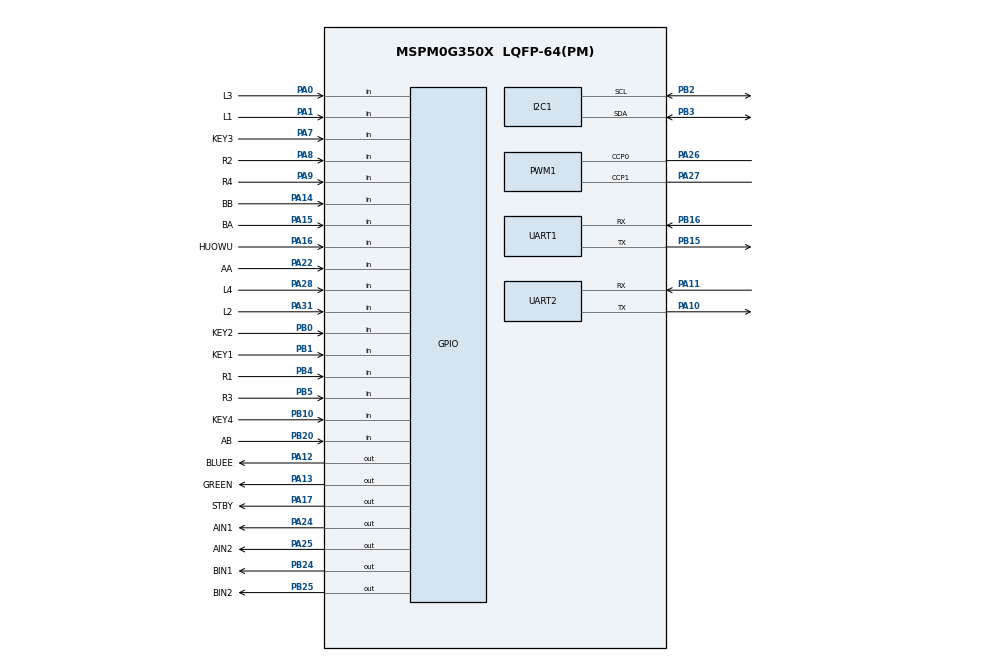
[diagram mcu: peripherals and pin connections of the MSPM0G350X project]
/**
 * @cliArgs --device "MSPM0G350X" --part "Default" --package "LQFP-64(PM)" --product "mspm0_sdk@2.11.00.07"
 * @versions {"tool":"1.26.2+4477"}
 */

/**
 * Import the modules used in this configuration.
 */
const GPIO   = scripting.addModule("/ti/driverlib/GPIO", {}, false);
const GPIO1  = GPIO.addInstance();
const GPIO2  = GPIO.addInstance();
const GPIO3  = GPIO.addInstance();
const GPIO4  = GPIO.addInstance();
const I2C    = scripting.addModule("/ti/driverlib/I2C", {}, false);
const I2C1   = I2C.addInstance();
const PWM    = scripting.addModule("/ti/driverlib/PWM", {}, false);
const PWM1   = PWM.addInstance();
const SYSCTL = scripting.addModule("/ti/driverlib/SYSCTL");
const TIMER  = scripting.addModule("/ti/driverlib/TIMER", {}, false);
const TIMER1 = TIMER.addInstance();
const UART   = scripting.addModule("/ti/driverlib/UART", {}, false);
const UART1  = UART.addInstance();
const UART2  = UART.addInstance();

/**
 * Write custom configuration values to the imported modules.
 */
const divider9       = system.clockTree["UDIV"];
divider9.divideValue = 2;

const multiplier2         = system.clockTree["PLL_QDIV"];
multiplier2.multiplyValue = 4;

const mux4       = system.clockTree["EXHFMUX"];
mux4.inputSelect = "EXHFMUX_XTAL";

const mux8       = system.clockTree["HSCLKMUX"];
mux8.inputSelect = "HSCLKMUX_SYSPLL0";

const mux12       = system.clockTree["SYSPLLMUX"];
mux12.inputSelect = "zSYSPLLMUX_HFCLK";

const pinFunction4          = system.clockTree["HFXT"];
pinFunction4.enable         = true;
pinFunction4.HFCLKMonitor   = true;
pinFunction4.HFXTStartup    = 10;
pinFunction4.inputFreq      = 40;

GPIO1.$name                         = "HUIDU";
GPIO1.associatedPins.create(8);
GPIO1.associatedPins[0].$name       = "L4";
GPIO1.associatedPins[0].direction   = "INPUT";
GPIO1.associatedPins[0].pin.$assign = "PA28";
GPIO1.associatedPins[1].$name       = "L3";
GPIO1.associatedPins[1].direction   = "INPUT";
GPIO1.associatedPins[1].pin.$assign = "PA0";
GPIO1.associatedPins[2].$name       = "L2";
GPIO1.associatedPins[2].direction   = "INPUT";
GPIO1.associatedPins[2].pin.$assign = "PA31";
GPIO1.associatedPins[3].$name       = "L1";
GPIO1.associatedPins[3].direction   = "INPUT";
GPIO1.associatedPins[3].pin.$assign = "PA1";
GPIO1.associatedPins[4].$name       = "R1";
GPIO1.associatedPins[4].direction   = "INPUT";
GPIO1.associatedPins[4].pin.$assign = "PB4";
GPIO1.associatedPins[5].$name       = "R2";
GPIO1.associatedPins[5].direction   = "INPUT";
GPIO1.associatedPins[5].pin.$assign = "PA8";
GPIO1.associatedPins[6].$name       = "R3";
GPIO1.associatedPins[6].direction   = "INPUT";
GPIO1.associatedPins[6].pin.$assign = "PB5";
GPIO1.associatedPins[7].$name       = "R4";
GPIO1.associatedPins[7].direction   = "INPUT";
GPIO1.associatedPins[7].pin.$assign = "PA9";

const Board = scripting.addModule("/ti/driverlib/Board", {}, false);

GPIO2.$name                              = "DC_MOTOR";
GPIO2.associatedPins.create(9);
GPIO2.associatedPins[0].$name            = "AIN1";
GPIO2.associatedPins[0].pin.$assign      = "PA24";
GPIO2.associatedPins[1].$name            = "AIN2";
GPIO2.associatedPins[1].pin.$assign      = "PA25";
GPIO2.associatedPins[2].$name            = "BIN1";
GPIO2.associatedPins[2].pin.$assign      = "PB24";
GPIO2.associatedPins[3].$name            = "BIN2";
GPIO2.associatedPins[3].pin.$assign      = "PB25";
GPIO2.associatedPins[4].$name            = "AA";
GPIO2.associatedPins[4].direction        = "INPUT";
GPIO2.associatedPins[4].interruptEn      = true;
GPIO2.associatedPins[4].polarity         = "RISE";
GPIO2.associatedPins[4].internalResistor = "PULL_DOWN";
GPIO2.associatedPins[4].pin.$assign      = "PA22";
GPIO2.associatedPins[5].$name            = "AB";
GPIO2.associatedPins[5].direction        = "INPUT";
GPIO2.associatedPins[5].internalResistor = "PULL_DOWN";
GPIO2.associatedPins[5].pin.$assign      = "PB20";
GPIO2.associatedPins[6].$name            = "BA";
GPIO2.associatedPins[6].direction        = "INPUT";
GPIO2.associatedPins[6].interruptEn      = true;
GPIO2.associatedPins[6].polarity         = "RISE";
GPIO2.associatedPins[6].internalResistor = "PULL_DOWN";
GPIO2.associatedPins[6].pin.$assign      = "PA15";
GPIO2.associatedPins[7].$name            = "BB";
GPIO2.associatedPins[7].direction        = "INPUT";
GPIO2.associatedPins[7].internalResistor = "PULL_DOWN";
GPIO2.associatedPins[7].pin.$assign      = "PA14";
GPIO2.associatedPins[8].$name            = "STBY";
GPIO2.associatedPins[8].pin.$assign      = "PA17";

GPIO3.$name                         = "LED";
GPIO3.associatedPins.create(2);
GPIO3.associatedPins[0].$name       = "GREEN";
GPIO3.associatedPins[0].pin.$assign = "PA13";
GPIO3.associatedPins[1].$name       = "BLUEE";
GPIO3.associatedPins[1].pin.$assign = "PA12";

GPIO4.$name                              = "KEY";
GPIO4.associatedPins.create(5);
GPIO4.associatedPins[0].direction        = "INPUT";
GPIO4.associatedPins[0].internalResistor = "PULL_UP";
GPIO4.associatedPins[0].$name            = "HUOWU";
GPIO4.associatedPins[0].pin.$assign      = "PA16";
GPIO4.associatedPins[1].$name            = "KEY1";
GPIO4.associatedPins[1].direction        = "INPUT";
GPIO4.associatedPins[1].internalResistor = "PULL_UP";
GPIO4.associatedPins[1].pin.$assign      = "PB1";
GPIO4.associatedPins[2].$name            = "KEY2";
GPIO4.associatedPins[2].direction        = "INPUT";
GPIO4.associatedPins[2].internalResistor = "PULL_UP";
GPIO4.associatedPins[2].pin.$assign      = "PB0";
GPIO4.associatedPins[3].$name            = "KEY3";
GPIO4.associatedPins[3].direction        = "INPUT";
GPIO4.associatedPins[3].internalResistor = "PULL_UP";
GPIO4.associatedPins[3].pin.$assign      = "PA7";
GPIO4.associatedPins[4].$name            = "KEY4";
GPIO4.associatedPins[4].direction        = "INPUT";
GPIO4.associatedPins[4].internalResistor = "PULL_UP";
GPIO4.associatedPins[4].pin.$assign      = "PB10";

I2C1.$name                             = "OLED";
I2C1.peripheral.$assign                = "I2C1";
I2C1.peripheral.sdaPin.$assign         = "PB3";
I2C1.peripheral.sclPin.$assign         = "PB2";
I2C1.sdaPinConfig.hideOutputInversion  = scripting.forceWrite(false);
I2C1.sdaPinConfig.onlyInternalResistor = scripting.forceWrite(false);
I2C1.sdaPinConfig.passedPeripheralType = scripting.forceWrite("Digital");
I2C1.sdaPinConfig.$name                = "ti_driverlib_gpio_GPIOPinGeneric2";
I2C1.sclPinConfig.hideOutputInversion  = scripting.forceWrite(false);
I2C1.sclPinConfig.onlyInternalResistor = scripting.forceWrite(false);
I2C1.sclPinConfig.passedPeripheralType = scripting.forceWrite("Digital");
I2C1.sclPinConfig.$name                = "ti_driverlib_gpio_GPIOPinGeneric3";

PWM1.$name                              = "MOTOR_PWMAB";
PWM1.timerStartTimer                    = true;
PWM1.pwmMode                            = "EDGE_ALIGN_UP";
PWM1.clockDivider                       = 2;
PWM1.timerCount                         = 10000;
PWM1.peripheral.$assign                 = "TIMG7";
PWM1.peripheral.ccp0Pin.$assign         = "PA26";
PWM1.peripheral.ccp1Pin.$assign         = "PA27";
PWM1.PWM_CHANNEL_0.$name                = "ti_driverlib_pwm_PWMTimerCC0";
PWM1.PWM_CHANNEL_1.$name                = "ti_driverlib_pwm_PWMTimerCC1";
PWM1.ccp0PinConfig.direction            = scripting.forceWrite("OUTPUT");
PWM1.ccp0PinConfig.hideOutputInversion  = scripting.forceWrite(false);
PWM1.ccp0PinConfig.onlyInternalResistor = scripting.forceWrite(false);
PWM1.ccp0PinConfig.passedPeripheralType = scripting.forceWrite("Digital");
PWM1.ccp0PinConfig.$name                = "ti_driverlib_gpio_GPIOPinGeneric0";
PWM1.ccp1PinConfig.direction            = scripting.forceWrite("OUTPUT");
PWM1.ccp1PinConfig.hideOutputInversion  = scripting.forceWrite(false);
PWM1.ccp1PinConfig.onlyInternalResistor = scripting.forceWrite(false);
PWM1.ccp1PinConfig.passedPeripheralType = scripting.forceWrite("Digital");
PWM1.ccp1PinConfig.$name                = "ti_driverlib_gpio_GPIOPinGeneric1";

SYSCTL.validateClkStatus     = true;
SYSCTL.forceDefaultClkConfig = true;
SYSCTL.clockTreeEn           = true;

TIMER1.$name              = "PID";
TIMER1.timerMode          = "PERIODIC_UP";
TIMER1.timerClkPrescale   = 100;
TIMER1.timerStartTimer    = true;
TIMER1.timerPeriod        = "10 ms";
TIMER1.interrupts         = ["LOAD"];
TIMER1.peripheral.$assign = "TIMA0";

UART1.$name                            = "K230";
UART1.targetBaudRate                   = 115200;
UART1.enableFIFO                       = true;
UART1.rxFifoThreshold                  = "DL_UART_RX_FIFO_LEVEL_ONE_ENTRY";
UART1.enabledInterrupts                = ["RX"];
UART1.peripheral.$assign               = "UART2";
UART1.peripheral.rxPin.$assign         = "PB16";
UART1.peripheral.txPin.$assign         = "PB15";
UART1.txPinConfig.$name                = "ti_driverlib_gpio_GPIOPinGeneric4";
UART1.txPinConfig.direction            = scripting.forceWrite("OUTPUT");
UART1.txPinConfig.hideOutputInversion  = scripting.forceWrite(false);
UART1.txPinConfig.onlyInternalResistor = scripting.forceWrite(false);
UART1.txPinConfig.passedPeripheralType = scripting.forceWrite("Digital");
UART1.rxPinConfig.$name                = "ti_driverlib_gpio_GPIOPinGeneric5";
UART1.rxPinConfig.hideOutputInversion  = scripting.forceWrite(false);
UART1.rxPinConfig.onlyInternalResistor = scripting.forceWrite(false);
UART1.rxPinConfig.passedPeripheralType = scripting.forceWrite("Digital");

UART2.targetBaudRate                   = 115200;
UART2.enabledInterrupts                = ["RX"];
UART2.$name                            = "DEBUG";
UART2.peripheral.$assign               = "UART0";
UART2.peripheral.rxPin.$assign         = "PA11";
UART2.peripheral.txPin.$assign         = "PA10";
UART2.txPinConfig.$name                = "ti_driverlib_gpio_GPIOPinGeneric6";
UART2.txPinConfig.direction            = scripting.forceWrite("OUTPUT");
UART2.txPinConfig.hideOutputInversion  = scripting.forceWrite(false);
UART2.txPinConfig.onlyInternalResistor = scripting.forceWrite(false);
UART2.txPinConfig.passedPeripheralType = scripting.forceWrite("Digital");
UART2.rxPinConfig.$name                = "ti_driverlib_gpio_GPIOPinGeneric7";
UART2.rxPinConfig.hideOutputInversion  = scripting.forceWrite(false);
UART2.rxPinConfig.onlyInternalResistor = scripting.forceWrite(false);
UART2.rxPinConfig.passedPeripheralType = scripting.forceWrite("Digital");

/**
 * Pinmux solution for unlocked pins/peripherals. This ensures that minor changes to the automatic solver in a future
 * version of the tool will not impact the pinmux you originally saw.  These lines can be completely deleted in order to
 * re-solve from scratch.
 */
pinFunction4.peripheral.$suggestSolution           = "SYSCTL";
pinFunction4.peripheral.hfxInPin.$suggestSolution  = "PA5";
pinFunction4.peripheral.hfxOutPin.$suggestSolution = "PA6";
Board.peripheral.$suggestSolution                  = "DEBUGSS";
Board.peripheral.swclkPin.$suggestSolution         = "PA20";
Board.peripheral.swdioPin.$suggestSolution         = "PA19";
